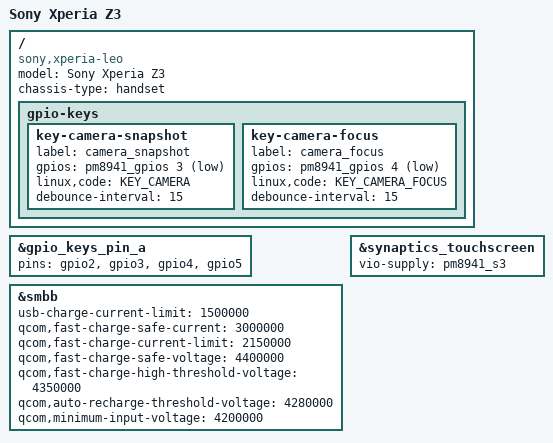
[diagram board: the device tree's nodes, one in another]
// SPDX-License-Identifier: GPL-2.0
#include "qcom-msm8974pro-sony-xperia-shinano-common.dtsi"

/ {
	model = "Sony Xperia Z3";
	compatible = "sony,xperia-leo", "qcom,msm8974pro", "qcom,msm8974";
	chassis-type = "handset";

	gpio-keys {
		key-camera-snapshot {
			label = "camera_snapshot";
			gpios = <&pm8941_gpios 3 GPIO_ACTIVE_LOW>;
			linux,code = <KEY_CAMERA>;
			debounce-interval = <15>;
		};

		key-camera-focus {
			label = "camera_focus";
			gpios = <&pm8941_gpios 4 GPIO_ACTIVE_LOW>;
			linux,code = <KEY_CAMERA_FOCUS>;
			debounce-interval = <15>;
		};
	};
};

&gpio_keys_pin_a {
	pins = "gpio2", "gpio3", "gpio4", "gpio5";
};

&smbb {
	usb-charge-current-limit = <1500000>;
	qcom,fast-charge-safe-current = <3000000>;
	qcom,fast-charge-current-limit = <2150000>;
	qcom,fast-charge-safe-voltage = <4400000>;
	qcom,fast-charge-high-threshold-voltage = <4350000>;
	qcom,auto-recharge-threshold-voltage = <4280000>;
	qcom,minimum-input-voltage = <4200000>;

	status = "okay";
};

&synaptics_touchscreen {
	vio-supply = <&pm8941_s3>;
};
